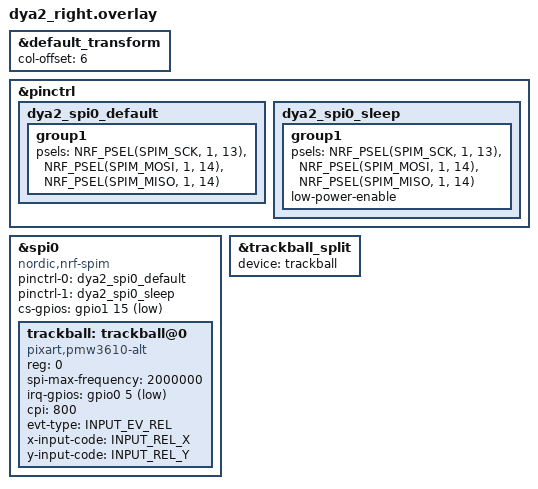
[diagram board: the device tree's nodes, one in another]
#include <zephyr/dt-bindings/input/input-event-codes.h>
#include "dya2.dtsi"

&default_transform {
    col-offset = <6>;
};

&pinctrl {
    dya2_spi0_default: dya2_spi0_default {
        group1 {
            psels = <NRF_PSEL(SPIM_SCK, 1, 13)>,
                    <NRF_PSEL(SPIM_MOSI, 1, 14)>,
                    <NRF_PSEL(SPIM_MISO, 1, 14)>;
        };
    };

    dya2_spi0_sleep: dya2_spi0_sleep {
        group1 {
            psels = <NRF_PSEL(SPIM_SCK, 1, 13)>,
                    <NRF_PSEL(SPIM_MOSI, 1, 14)>,
                    <NRF_PSEL(SPIM_MISO, 1, 14)>;
            low-power-enable;
        };
    };
};

&spi0 {
    status = "okay";
    compatible = "nordic,nrf-spim";
    pinctrl-0 = <&dya2_spi0_default>;
    pinctrl-1 = <&dya2_spi0_sleep>;
    pinctrl-names = "default", "sleep";
    cs-gpios = <&gpio1 15 GPIO_ACTIVE_LOW>; /* D10 */

    trackball: trackball@0 {
        status = "okay";
        compatible = "pixart,pmw3610-alt";
        reg = <0>;
        spi-max-frequency = <2000000>;
        irq-gpios = <&gpio0 5 (GPIO_ACTIVE_LOW | GPIO_PULL_UP)>; /* D5 */
        cpi = <800>;
        evt-type = <INPUT_EV_REL>;
        x-input-code = <INPUT_REL_X>;
        y-input-code = <INPUT_REL_Y>;
    };
};

&trackball_split {
    device = <&trackball>;
};
